AUTOSAR XML (schema 00051)
package /Components
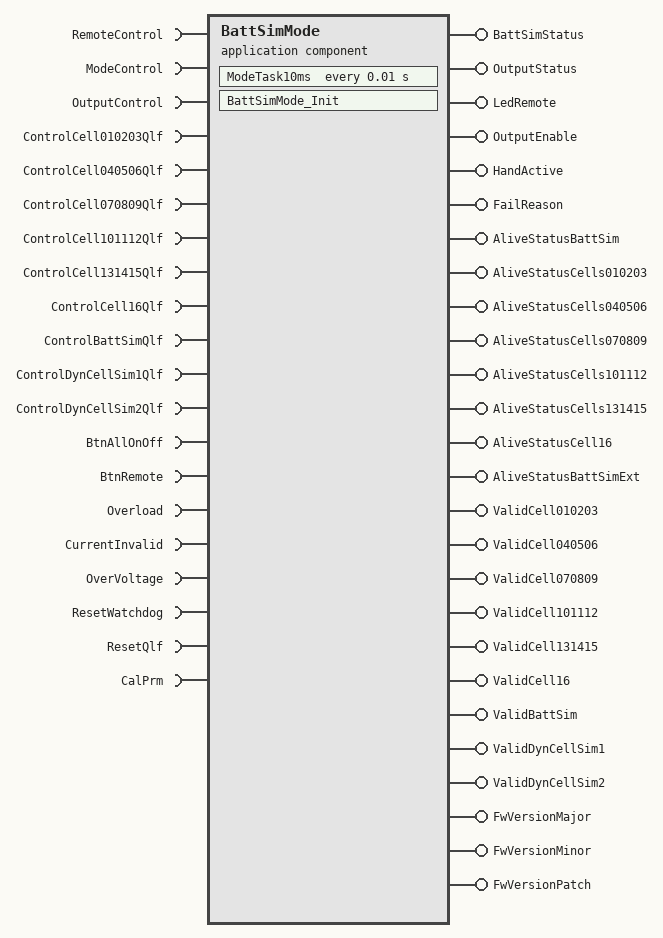
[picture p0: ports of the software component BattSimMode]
  application sw component type BattSimMode
    19 x require port:
      RemoteControl: nonqueued-receiver-com-spec{data-element=RemoteControl, init-value=0}, required-interface=RemoteControl
      ModeControl: nonqueued-receiver-com-spec{data-element=ModeControl, init-value=0}, required-interface=ModeControl
      OutputControl: nonqueued-receiver-com-spec{data-element=OutputControl, init-value=0}, required-interface=OutputControl
      ControlCell010203Qlf: nonqueued-receiver-com-spec{data-element=ControlCell010203Qlf, init-value=0}, required-interface=ControlCell010203Qlf
      ControlCell040506Qlf: nonqueued-receiver-com-spec{data-element=ControlCell040506Qlf, init-value=0}, required-interface=ControlCell040506Qlf
      ControlCell070809Qlf: nonqueued-receiver-com-spec{data-element=ControlCell070809Qlf, init-value=0}, required-interface=ControlCell070809Qlf
      ControlCell101112Qlf: nonqueued-receiver-com-spec{data-element=ControlCell101112Qlf, init-value=0}, required-interface=ControlCell101112Qlf
      ControlCell131415Qlf: nonqueued-receiver-com-spec{data-element=ControlCell131415Qlf, init-value=0}, required-interface=ControlCell131415Qlf
      ControlCell16Qlf: nonqueued-receiver-com-spec{data-element=ControlCell16Qlf, init-value=0}, required-interface=ControlCell16Qlf
      ControlBattSimQlf: nonqueued-receiver-com-spec{data-element=ControlBattSimQlf, init-value=0}, required-interface=ControlBattSimQlf
      ControlDynCellSim1Qlf: nonqueued-receiver-com-spec{data-element=ControlDynCellSim1Qlf, init-value=0}, required-interface=ControlDynCellSim1Qlf
      ControlDynCellSim2Qlf: nonqueued-receiver-com-spec{data-element=ControlDynCellSim2Qlf, init-value=0}, required-interface=ControlDynCellSim2Qlf
      BtnAllOnOff: nonqueued-receiver-com-spec{data-element=BtnAllOnOff, init-value=0}, required-interface=BtnAllOnOff
      BtnRemote: nonqueued-receiver-com-spec{data-element=BtnRemote, init-value=0}, required-interface=BtnRemote
      Overload: nonqueued-receiver-com-spec{data-element=Overload, init-value=0}, required-interface=Overload
      CurrentInvalid: nonqueued-receiver-com-spec{data-element=CurrentInvalid, init-value=0}, required-interface=CurrentInvalid
      OverVoltage: nonqueued-receiver-com-spec{data-element=OverVoltage, init-value=0}, required-interface=OverVoltage
      ResetWatchdog: nonqueued-receiver-com-spec{data-element=ResetWatchdog, init-value=0}, required-interface=ResetWatchdog
      ResetQlf: nonqueued-receiver-com-spec{data-element=ResetQlf, init-value=0}, required-interface=ResetQlf
    26 x provide port:
      BattSimStatus: nonqueued-sender-com-spec{data-element=BattSimStatus, init-value=0}, provided-interface=BattSimStatus
      OutputStatus: nonqueued-sender-com-spec{data-element=OutputStatus, init-value=0}, provided-interface=OutputStatus
      LedRemote: nonqueued-sender-com-spec{data-element=LedRemote, init-value=0}, provided-interface=LedRemote
      OutputEnable: nonqueued-sender-com-spec{data-element=OutputEnable, init-value=0}, provided-interface=OutputEnable
      HandActive: nonqueued-sender-com-spec{data-element=HandActive, init-value=0}, provided-interface=HandActive
      FailReason: nonqueued-sender-com-spec{data-element=FailReason, init-value=0}, provided-interface=FailReason
      AliveStatusBattSim: nonqueued-sender-com-spec{data-element=AliveStatusBattSim, init-value=0}, provided-interface=AliveStatusBattSim
      AliveStatusCells010203: nonqueued-sender-com-spec{data-element=AliveStatusCells010203, init-value=0}, provided-interface=AliveStatusCells010203
      AliveStatusCells040506: nonqueued-sender-com-spec{data-element=AliveStatusCells040506, init-value=0}, provided-interface=AliveStatusCells040506
      AliveStatusCells070809: nonqueued-sender-com-spec{data-element=AliveStatusCells070809, init-value=0}, provided-interface=AliveStatusCells070809
      AliveStatusCells101112: nonqueued-sender-com-spec{data-element=AliveStatusCells101112, init-value=0}, provided-interface=AliveStatusCells101112
      AliveStatusCells131415: nonqueued-sender-com-spec{data-element=AliveStatusCells131415, init-value=0}, provided-interface=AliveStatusCells131415
      AliveStatusCell16: nonqueued-sender-com-spec{data-element=AliveStatusCell16, init-value=0}, provided-interface=AliveStatusCell16
      AliveStatusBattSimExt: nonqueued-sender-com-spec{data-element=AliveStatusBattSimExt, init-value=0}, provided-interface=AliveStatusBattSimExt
      ValidCell010203: nonqueued-sender-com-spec{data-element=ValidCell010203, init-value=0}, provided-interface=ValidCell010203
      ValidCell040506: nonqueued-sender-com-spec{data-element=ValidCell040506, init-value=0}, provided-interface=ValidCell040506
      ValidCell070809: nonqueued-sender-com-spec{data-element=ValidCell070809, init-value=0}, provided-interface=ValidCell070809
      ValidCell101112: nonqueued-sender-com-spec{data-element=ValidCell101112, init-value=0}, provided-interface=ValidCell101112
      ValidCell131415: nonqueued-sender-com-spec{data-element=ValidCell131415, init-value=0}, provided-interface=ValidCell131415
      ValidCell16: nonqueued-sender-com-spec{data-element=ValidCell16, init-value=0}, provided-interface=ValidCell16
      ValidBattSim: nonqueued-sender-com-spec{data-element=ValidBattSim, init-value=0}, provided-interface=ValidBattSim
      ValidDynCellSim1: nonqueued-sender-com-spec{data-element=ValidDynCellSim1, init-value=0}, provided-interface=ValidDynCellSim1
      ValidDynCellSim2: nonqueued-sender-com-spec{data-element=ValidDynCellSim2, init-value=0}, provided-interface=ValidDynCellSim2
      FwVersionMajor: nonqueued-sender-com-spec{data-element=FwVersionMajor, init-value=0}, provided-interface=FwVersionMajor
      FwVersionMinor: nonqueued-sender-com-spec{data-element=FwVersionMinor, init-value=0}, provided-interface=FwVersionMinor
      FwVersionPatch: nonqueued-sender-com-spec{data-element=FwVersionPatch, init-value=0}, provided-interface=FwVersionPatch
    require port CalPrm: required-interface=CalPrm
      required-com-specs:
        init-value=CalPrm_ButtonDebounce_cycles:3, parameter=ButtonDebounce_cycles
        init-value=CalPrm_VersionMajor:0, parameter=VersionMajor
        init-value=CalPrm_VersionMinor:5, parameter=VersionMinor
        init-value=CalPrm_VersionPatch:0, parameter=VersionPatch
    behavior BattSimMode_IB: handle-termination-and-restart=NO-SUPPORT
      timing event Event_ModeTask10ms: start-on-event=ModeTask10ms, period=0.01
      runnable BattSimMode_Init
        data-send-points:
          access OUT_FwVersionMajor_FwVersionMajor: accessed-variable=FwVersionMajor.FwVersionMajor
          access OUT_FwVersionMinor_FwVersionMinor: accessed-variable=FwVersionMinor.FwVersionMinor
          access OUT_FwVersionPatch_FwVersionPatch: accessed-variable=FwVersionPatch.FwVersionPatch
        parameter access CALPRM_CalPrm_VersionMajor: accessed-parameter=CalPrm.VersionMajor
        parameter access CALPRM_CalPrm_VersionMinor: accessed-parameter=CalPrm.VersionMinor
        parameter access CALPRM_CalPrm_VersionPatch: accessed-parameter=CalPrm.VersionPatch
      runnable ModeTask10ms
        data-receive-point-by-arguments:
          19 x access:
            IN_BtnAllOnOff_BtnAllOnOff: accessed-variable=BtnAllOnOff.BtnAllOnOff
            IN_BtnRemote_BtnRemote: accessed-variable=BtnRemote.BtnRemote
            IN_ControlBattSimQlf_ControlBattSimQlf: accessed-variable=ControlBattSimQlf.ControlBattSimQlf
            IN_ControlCell010203Qlf_ControlCell010203Qlf: accessed-variable=ControlCell010203Qlf.ControlCell010203Qlf
            IN_ControlCell040506Qlf_ControlCell040506Qlf: accessed-variable=ControlCell040506Qlf.ControlCell040506Qlf
            IN_ControlCell070809Qlf_ControlCell070809Qlf: accessed-variable=ControlCell070809Qlf.ControlCell070809Qlf
            IN_ControlCell101112Qlf_ControlCell101112Qlf: accessed-variable=ControlCell101112Qlf.ControlCell101112Qlf
            IN_ControlCell131415Qlf_ControlCell131415Qlf: accessed-variable=ControlCell131415Qlf.ControlCell131415Qlf
            IN_ControlCell16Qlf_ControlCell16Qlf: accessed-variable=ControlCell16Qlf.ControlCell16Qlf
            IN_ControlDynCellSim1Qlf_ControlDynCellSim1Qlf: accessed-variable=ControlDynCellSim1Qlf.ControlDynCellSim1Qlf
            IN_ControlDynCellSim2Qlf_ControlDynCellSim2Qlf: accessed-variable=ControlDynCellSim2Qlf.ControlDynCellSim2Qlf
            IN_CurrentInvalid_CurrentInvalid: accessed-variable=CurrentInvalid.CurrentInvalid
            IN_ModeControl_ModeControl: accessed-variable=ModeControl.ModeControl
            IN_OutputControl_OutputControl: accessed-variable=OutputControl.OutputControl
            IN_OverVoltage_OverVoltage: accessed-variable=OverVoltage.OverVoltage
            IN_Overload_Overload: accessed-variable=Overload.Overload
            IN_RemoteControl_RemoteControl: accessed-variable=RemoteControl.RemoteControl
            IN_ResetQlf_ResetQlf: accessed-variable=ResetQlf.ResetQlf
            IN_ResetWatchdog_ResetWatchdog: accessed-variable=ResetWatchdog.ResetWatchdog
        data-send-points:
          26 x access:
            OUT_BattSimStatus_BattSimStatus: accessed-variable=BattSimStatus.BattSimStatus
            OUT_OutputStatus_OutputStatus: accessed-variable=OutputStatus.OutputStatus
            OUT_LedRemote_LedRemote: accessed-variable=LedRemote.LedRemote
            OUT_OutputEnable_OutputEnable: accessed-variable=OutputEnable.OutputEnable
            OUT_HandActive_HandActive: accessed-variable=HandActive.HandActive
            OUT_FailReason_FailReason: accessed-variable=FailReason.FailReason
            OUT_AliveStatusBattSim_AliveStatusBattSim: accessed-variable=AliveStatusBattSim.AliveStatusBattSim
            OUT_AliveStatusCells010203_AliveStatusCells010203: accessed-variable=AliveStatusCells010203.AliveStatusCells010203
            OUT_AliveStatusCells040506_AliveStatusCells040506: accessed-variable=AliveStatusCells040506.AliveStatusCells040506
            OUT_AliveStatusCells070809_AliveStatusCells070809: accessed-variable=AliveStatusCells070809.AliveStatusCells070809
            OUT_AliveStatusCells101112_AliveStatusCells101112: accessed-variable=AliveStatusCells101112.AliveStatusCells101112
            OUT_AliveStatusCells131415_AliveStatusCells131415: accessed-variable=AliveStatusCells131415.AliveStatusCells131415
            OUT_AliveStatusCell16_AliveStatusCell16: accessed-variable=AliveStatusCell16.AliveStatusCell16
            OUT_AliveStatusBattSimExt_AliveStatusBattSimExt: accessed-variable=AliveStatusBattSimExt.AliveStatusBattSimExt
            OUT_ValidCell010203_ValidCell010203: accessed-variable=ValidCell010203.ValidCell010203
            OUT_ValidCell040506_ValidCell040506: accessed-variable=ValidCell040506.ValidCell040506
            OUT_ValidCell070809_ValidCell070809: accessed-variable=ValidCell070809.ValidCell070809
            OUT_ValidCell101112_ValidCell101112: accessed-variable=ValidCell101112.ValidCell101112
            OUT_ValidCell131415_ValidCell131415: accessed-variable=ValidCell131415.ValidCell131415
            OUT_ValidCell16_ValidCell16: accessed-variable=ValidCell16.ValidCell16
            OUT_ValidBattSim_ValidBattSim: accessed-variable=ValidBattSim.ValidBattSim
            OUT_ValidDynCellSim1_ValidDynCellSim1: accessed-variable=ValidDynCellSim1.ValidDynCellSim1
            OUT_ValidDynCellSim2_ValidDynCellSim2: accessed-variable=ValidDynCellSim2.ValidDynCellSim2
            OUT_FwVersionMajor_FwVersionMajor: accessed-variable=FwVersionMajor.FwVersionMajor
            OUT_FwVersionMinor_FwVersionMinor: accessed-variable=FwVersionMinor.FwVersionMinor
            OUT_FwVersionPatch_FwVersionPatch: accessed-variable=FwVersionPatch.FwVersionPatch
        4 x parameter access:
          CALPRM_CalPrm_ButtonDebounce_cycles: accessed-parameter=CalPrm.ButtonDebounce_cycles
          CALPRM_CalPrm_VersionMajor: accessed-parameter=CalPrm.VersionMajor
          CALPRM_CalPrm_VersionMinor: accessed-parameter=CalPrm.VersionMinor
          CALPRM_CalPrm_VersionPatch: accessed-parameter=CalPrm.VersionPatch
